# DSC28027 register map
Vendor: Beijing Haawking Technology Co.,Ltd.; File version: 1.0
Registers are 32-bit, read-write, reset 0x0 unless marked. A register's access mark holds for its fields unless they carry their own. Offsets are from the block's base; [hi:lo] are bit positions; {n}, {i} and the like mark numbered series.

## GPIO — General Purpose Input/Output Interface
Base 0x50200000
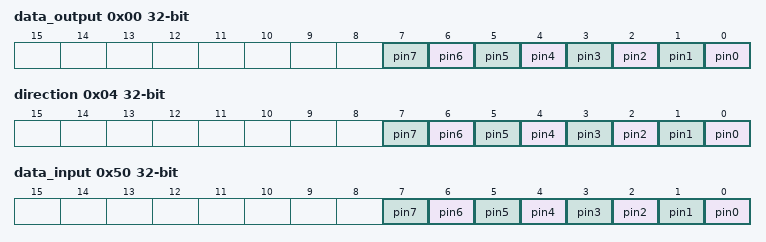
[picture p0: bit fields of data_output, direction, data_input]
0x00 data_output — Data (output) registers
  [n] pin{n} (n=0..7)
0x04 direction — Data direction registers
  [n] pin{n} (n=0..7)
    0=input (Pin is input); 1=output (Pin is output)
0x08 source — Data source registers
0x30 interrupt_enable — Interrupt enable/disable registers
0x34 interrupt_mask — Interrupt mask registers
0x38 interrupt_level — Interrupt level registers
0x3C interrupt_polarity — Interrupt polarity registers
0x40 interrupt_status — Interrupt status registers
0x44 interrupt_status_raw — Raw interrupt status registers
0x48 interrupt_debounce — Interrupt debounce registers
0x4C interrupt_clear — Registers for clearing interrupts
0x50 data_input — External port (data input) registers
  [n] pin{n} (n=0..7)
0x60 sync_level — Sync level registers
0x64 id_code
0x68 interrupt_bothedge — Interrupt both edge type

## UART1 — Universal Asynchronous Receiver-Transmitter 1
Base 0x50210000
Same registers: UART2 0x50220000, UART3 0x50230000
0x00 rbr_dll_thr — Receive Buffer Register / Divisor Latch (Low) / Transmit Holding Register (depending on context and R/W)
0x04 dlh_ier — Divisor Latch (High) / Interrupt Enable Register
0x08 fcr_iir — FIFO Control Register / Interrupt Identification Register
0x0C lcr — Line Control Register
0x10 mcr — Modem Control Register
0x14 lsr — Line Status Register
0x18 msr — Modem Status Register
0x1C scr — Scratchpad Register
0x20 lpdll — Low Power Divisor Latch (Low) Register
0x24 lpdlh — Low Power Divisor Latch (High) Register
{0x30+4i} srbr_sthr[{i}] (i=0..15) — Shadow Receive Buffer Register / Shadow Transmit Holding Register (depending on R/W)
0x70 far — FIFO Access Register
0x74 tfr — Transmit FIFO Read Register
0x78 rfw — Receive FIFO Write Register
0x7C usr — UART Status Register
0x80 tfl — Transmit FIFO Level
0x84 rfl — Receive FIFO Level
0x88 srr — Software Reset Register
0x8C srts — Shadow Request to Send Register
0x90 sbcr — Shadow Break Control Register
0x94 sdmam — Shadow DMA Mode
0x98 sfe — Shadow FIFO Enable
0x9C srt — Shadow RCVR Trigger Register
0xA0 stet — Shadow TX Empty Trigger Register
0xA4 htx — Halt TX Regster
0xA8 dmasa — DMA Software Acknowledge Register
0xAC tcr — Transfer Control Register
0xB0 de_en — DE Enable Register
0xB4 re_en — RE Enable Register
0xB8 det — DE Assertion Time Register
0xBC tat — Turn-Around Time Register
0xC0 dlf — Divisor Latch (Fractional) Register
0xC4 rar — Receive-Mode Address Register
0xC8 tar — Transmit-Mode Address Register
0xCC lcr_ext — Line Control Register (Extended)
0xF4 cpr — Component Parameter Register
0xF8 ucv — UART Component Version
0xFC ctr — Component Type Register

## SPI0 — Serial Peripheral Interface 0 (master)
Base 0x52000000
Same registers: SPI1 0x53000000
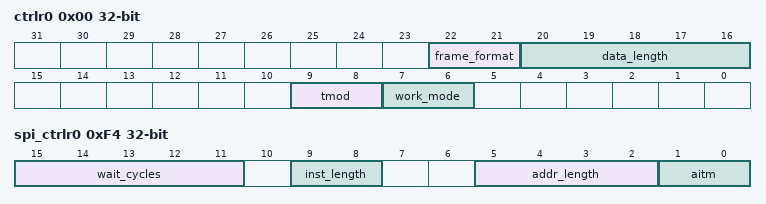
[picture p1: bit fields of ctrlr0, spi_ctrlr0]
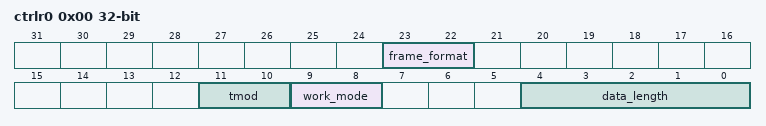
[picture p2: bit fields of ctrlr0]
0x00 ctrlr0 — Control Register 0
  [22:21] frame_format
    0=standard; 1=dual; 2=quad; 3=octal
  [20:16] data_length range 3..31 — DATA_BIT_LENGTH
  [9:8] tmod — TRANSFER_MODE
    0=trans_recv; 1=trans; 2=recv; 3=eerom
  [7:6] work_mode
    {v}=mode{v} (v=0..3)
0x04 ctrlr1 — Control Register 1
0x08 ssienr — Enable Register
0x0C mwcr — Microwire Control Register
0x10 ser — Slave Enable Register
0x14 baudr — Baud Rate Select
0x18 txftlr — Transmit FIFO Threshold Level
0x1C rxftlr — Receive FIFO Threshold Level
0x20 txflr — Transmit FIFO Level Register
0x24 rxflr — Receive FIFO Level Register
0x28 sr — Status Register
0x2C imr — Interrupt Mask Register
0x30 isr — Interrupt Status Register
0x34 risr — Raw Interrupt Status Register
0x38 txoicr — Transmit FIFO Overflow Interrupt Clear Register
0x3C rxoicr — Receive FIFO Overflow Interrupt Clear Register
0x40 rxuicr — Receive FIFO Underflow Interrupt Clear Register
0x44 msticr — Multi-Master Interrupt Clear Register
0x48 icr — Interrupt Clear Register
0x4C dmacr — DMA Control Register
0x50 dmatdlr — DMA Transmit Data Level
0x54 dmardlr — DMA Receive Data Level
0x58 idr — Identification Register
0x5C ssic_version_id — DWC_ssi component version
{0x60+4i} dr{i} (i=0..35) — Data Register
0xF0 rx_sample_delay
0xF4 spi_ctrlr0 — SPI Control Register
  [15:11] wait_cycles
  [9:8] inst_length — INSTRUCTION_LENGTH
  [5:2] addr_length
  [1:0] aitm — instruction_address_trans_mode
    0=standard; 1=addr_standard; 2=as_frame_format
0xFC xip_mode_bits
0x100 xip_incr_inst — XIP INCR transfer opcode
0x104 xip_wrap_inst — XIP WRAP transfer opcode
0x108 xip_ctrl — XIP Control Register
0x10C xip_ser — XIP Slave Enable Register
0x110 xrxoicr — XIP Receive FIFO Overflow Interrupt Clear Register
0x114 xip_cnt_time_out — XIP time out register for continuous transfers
0x118 endian

## SPI3 — Serial Peripheral Interface 3 (master)
Base 0x54000000
Registers as SPI0; these are added or differ:
0x00 ctrlr0 — Control Register 0
  [23:22] frame_format
    0=standard; 1=dual; 2=quad; 3=octal
  [11:10] tmod — TRANSFER_MODE
    0=trans_recv; 1=trans; 2=recv; 3=eerom
  [9:8] work_mode
    {v}=mode{v} (v=0..3)
  [4:0] data_length range 3..31 — DATA_BIT_LENGTH
